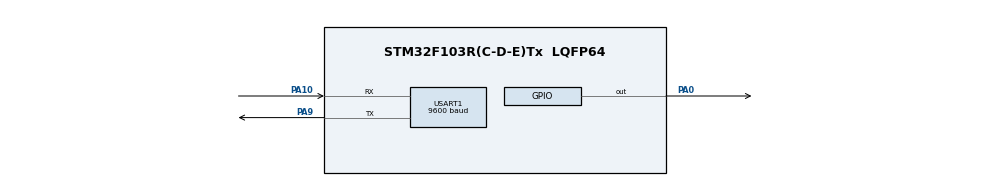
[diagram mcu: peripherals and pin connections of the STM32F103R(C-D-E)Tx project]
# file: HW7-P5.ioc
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Mcu.Family=STM32F1
Mcu.Name=STM32F103R(C-D-E)Tx
Mcu.Package=LQFP64
NVIC.PriorityGroup=NVIC_PRIORITYGROUP_4
NVIC.TIM1_CC_IRQn=true\:0\:0\:false\:false\:true\:true\:true\:true
NVIC.TIM1_UP_IRQn=true\:0\:0\:false\:false\:true\:true\:true\:true
NVIC.USART1_IRQn=true\:0\:0\:false\:false\:true\:true\:true\:true
PA0-WKUP.Signal=GPIO_Output
PA10.Mode=Asynchronous
PA10.Signal=USART1_RX
PA13.Mode=Serial_Wire
PA13.Signal=SYS_JTMS-SWDIO
PA14.Mode=Serial_Wire
PA14.Signal=SYS_JTCK-SWCLK
PA9.Mode=Asynchronous
PA9.Signal=USART1_TX
ProjectManager.HeapSize=0x200
ProjectManager.StackSize=0x400
ProjectManager.TargetToolchain=MDK-ARM V5.32
RCC.APB1Freq_Value=8000000
RCC.APB2Freq_Value=8000000
TIM1.AutoReloadPreload=TIM_AUTORELOAD_PRELOAD_ENABLE
TIM1.Channel-Output\ Compare1\ No\ Output=TIM_CHANNEL_1
TIM1.OCMode_1=TIM_OCMODE_TOGGLE
TIM1.Period=7999
TIM1.Prescaler=PonePRE
TIM1.Pulse-Output\ Compare1\ No\ Output=0
TIM1.TIM_MasterOutputTrigger=TIM_TRGO_UPDATE
USART1.BaudRate=9600
USART1.VirtualMode=VM_ASYNC
VP_TIM1_VS_ClockSourceINT.Mode=Internal
VP_TIM1_VS_no_output1.Mode=Output Compare1 No Output
board=custom

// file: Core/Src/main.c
/* USER CODE BEGIN Header */
/**
  ******************************************************************************
  * @file           : main.c
  * @brief          : Main program body
  ******************************************************************************
  * @attention
  *
  * Copyright (c) 2026 STMicroelectronics.
  * All rights reserved.
  *
  * This software is licensed under terms that can be found in the LICENSE file
  * in the root directory of this software component.
  * If no LICENSE file comes with this software, it is provided AS-IS.
  *
  ******************************************************************************
  */
/* USER CODE END Header */
#include "main.h"

/* USER CODE BEGIN Includes */
#include <stdio.h>
#include <stdlib.h>
#include <string.h>
/* USER CODE END Includes */

TIM_HandleTypeDef htim1;

UART_HandleTypeDef huart1;

/* USER CODE BEGIN PV */
uint16_t PonePRE = 79;
uint32_t target_freq = 50;   // Default 50 Hz startup
uint32_t target_duty = 2047; // Default 50% startup

uint8_t rx_buffer[2];
/* USER CODE END PV */

void SystemClock_Config(void);
static void MX_GPIO_Init(void);
static void MX_TIM1_Init(void);
static void MX_USART1_UART_Init(void);

/* USER CODE BEGIN 0 */
// UART RX Interrupt Callback to parse MATLAB commands
void HAL_UART_RxCpltCallback(UART_HandleTypeDef *huart)
{
    if (huart->Instance == USART1)
    {
        // 1. Extract the top 4 bits of the first byte to find the Command
        uint8_t command = (rx_buffer[0] >> 4) & 0x0F;

        // 2. Reconstruct the 12-bit data by combining the leftover 4 bits and the 8-bit Low Byte
        uint16_t value = ((rx_buffer[0] & 0x0F) << 8) | rx_buffer[1];

        // 3. Apply the data
        if (command == 1) // 1 = Frequency
        {
            target_freq = value;
        }
        else if (command == 2) // 2 = Duty Cycle
        {
            target_duty = value;
        }

        // Re-arm UART to wait for the next 2 bytes
        HAL_UART_Receive_IT(&huart1, rx_buffer, 2);
    }
}

// Timer Callbacks for PWM Generation
void HAL_TIM_PeriodElapsedCallback(TIM_HandleTypeDef *htim){
    if(TIM1->CCR1 > 0){
        HAL_GPIO_WritePin(GPIOA, GPIO_PIN_0, GPIO_PIN_SET);
    }
}

void HAL_TIM_OC_DelayElapsedCallback(TIM_HandleTypeDef *htim){
    if(htim->Channel == HAL_TIM_ACTIVE_CHANNEL_1){
        HAL_GPIO_WritePin(GPIOA, GPIO_PIN_0, GPIO_PIN_RESET);
    }
}
/* USER CODE END 0 */

int main(void)
{

  /* MCU Configuration--------------------------------------------------------*/

  /* Reset of all peripherals, Initializes the Flash interface and the Systick. */
  HAL_Init();

  /* Configure the system clock */
  SystemClock_Config();

  /* Initialize all configured peripherals */
  MX_GPIO_Init();
  MX_TIM1_Init();
  MX_USART1_UART_Init();
  /* USER CODE BEGIN 2 */
	// Start listening on UART immediately
	HAL_UART_Receive_IT(&huart1, rx_buffer, 2);
	/* USER CODE END 2 */

  /* Infinite loop */
  /* USER CODE BEGIN WHILE */
  while (1)
  {
		if (target_freq == 0)
      {
          HAL_TIM_Base_Stop_IT(&htim1);
          HAL_TIM_OC_Stop_IT(&htim1, TIM_CHANNEL_1);
          HAL_GPIO_WritePin(GPIOA, GPIO_PIN_0, GPIO_PIN_RESET);
      }
      else
      {
          HAL_TIM_Base_Start_IT(&htim1);
          HAL_TIM_OC_Start_IT(&htim1, TIM_CHANNEL_1);

          // 1. Calculate ARR based on target frequency
          uint32_t new_arr = (100000 / target_freq) - 1;
          if (new_arr > 65535) new_arr = 65535;

          // 2. Calculate CCR1 based on target duty (0 to 4095)
          uint32_t new_ccr = (target_duty * (new_arr + 1)) / 4095;

          // Apply hardware updates
          TIM1->ARR = new_arr;
          TIM1->CCR1 = new_ccr;
      }

      HAL_Delay(10);
    /* USER CODE END WHILE */

  }
}

void SystemClock_Config(void)
{
  RCC_OscInitTypeDef RCC_OscInitStruct = {0};
  RCC_ClkInitTypeDef RCC_ClkInitStruct = {0};

  /** Initializes the RCC Oscillators according to the specified parameters
  * in the RCC_OscInitTypeDef structure.
  */
  RCC_OscInitStruct.OscillatorType = RCC_OSCILLATORTYPE_HSI;
  RCC_OscInitStruct.HSIState = RCC_HSI_ON;
  RCC_OscInitStruct.HSICalibrationValue = RCC_HSICALIBRATION_DEFAULT;
  RCC_OscInitStruct.PLL.PLLState = RCC_PLL_NONE;
  if (HAL_RCC_OscConfig(&RCC_OscInitStruct) != HAL_OK)
  {
    Error_Handler();
  }

  /** Initializes the CPU, AHB and APB buses clocks
  */
  RCC_ClkInitStruct.ClockType = RCC_CLOCKTYPE_HCLK|RCC_CLOCKTYPE_SYSCLK
                              |RCC_CLOCKTYPE_PCLK1|RCC_CLOCKTYPE_PCLK2;
  RCC_ClkInitStruct.SYSCLKSource = RCC_SYSCLKSOURCE_HSI;
  RCC_ClkInitStruct.AHBCLKDivider = RCC_SYSCLK_DIV1;
  RCC_ClkInitStruct.APB1CLKDivider = RCC_HCLK_DIV1;
  RCC_ClkInitStruct.APB2CLKDivider = RCC_HCLK_DIV1;

  if (HAL_RCC_ClockConfig(&RCC_ClkInitStruct, FLASH_LATENCY_0) != HAL_OK)
  {
    Error_Handler();
  }
}

static void MX_TIM1_Init(void)
{

  TIM_ClockConfigTypeDef sClockSourceConfig = {0};
  TIM_MasterConfigTypeDef sMasterConfig = {0};
  TIM_OC_InitTypeDef sConfigOC = {0};
  TIM_BreakDeadTimeConfigTypeDef sBreakDeadTimeConfig = {0};

  htim1.Instance = TIM1;
  htim1.Init.Prescaler = PonePRE;
  htim1.Init.CounterMode = TIM_COUNTERMODE_UP;
  htim1.Init.Period = 7999;
  htim1.Init.ClockDivision = TIM_CLOCKDIVISION_DIV1;
  htim1.Init.RepetitionCounter = 0;
  htim1.Init.AutoReloadPreload = TIM_AUTORELOAD_PRELOAD_ENABLE;
  if (HAL_TIM_Base_Init(&htim1) != HAL_OK)
  {
    Error_Handler();
  }
  sClockSourceConfig.ClockSource = TIM_CLOCKSOURCE_INTERNAL;
  if (HAL_TIM_ConfigClockSource(&htim1, &sClockSourceConfig) != HAL_OK)
  {
    Error_Handler();
  }
  if (HAL_TIM_OC_Init(&htim1) != HAL_OK)
  {
    Error_Handler();
  }
  sMasterConfig.MasterOutputTrigger = TIM_TRGO_UPDATE;
  sMasterConfig.MasterSlaveMode = TIM_MASTERSLAVEMODE_DISABLE;
  if (HAL_TIMEx_MasterConfigSynchronization(&htim1, &sMasterConfig) != HAL_OK)
  {
    Error_Handler();
  }
  sConfigOC.OCMode = TIM_OCMODE_TOGGLE;
  sConfigOC.Pulse = 0;
  sConfigOC.OCPolarity = TIM_OCPOLARITY_HIGH;
  sConfigOC.OCNPolarity = TIM_OCNPOLARITY_HIGH;
  sConfigOC.OCFastMode = TIM_OCFAST_DISABLE;
  sConfigOC.OCIdleState = TIM_OCIDLESTATE_RESET;
  sConfigOC.OCNIdleState = TIM_OCNIDLESTATE_RESET;
  if (HAL_TIM_OC_ConfigChannel(&htim1, &sConfigOC, TIM_CHANNEL_1) != HAL_OK)
  {
    Error_Handler();
  }
  sBreakDeadTimeConfig.OffStateRunMode = TIM_OSSR_DISABLE;
  sBreakDeadTimeConfig.OffStateIDLEMode = TIM_OSSI_DISABLE;
  sBreakDeadTimeConfig.LockLevel = TIM_LOCKLEVEL_OFF;
  sBreakDeadTimeConfig.DeadTime = 0;
  sBreakDeadTimeConfig.BreakState = TIM_BREAK_DISABLE;
  sBreakDeadTimeConfig.BreakPolarity = TIM_BREAKPOLARITY_HIGH;
  sBreakDeadTimeConfig.AutomaticOutput = TIM_AUTOMATICOUTPUT_DISABLE;
  if (HAL_TIMEx_ConfigBreakDeadTime(&htim1, &sBreakDeadTimeConfig) != HAL_OK)
  {
    Error_Handler();
  }

}

static void MX_USART1_UART_Init(void)
{

  huart1.Instance = USART1;
  huart1.Init.BaudRate = 9600;
  huart1.Init.WordLength = UART_WORDLENGTH_8B;
  huart1.Init.StopBits = UART_STOPBITS_1;
  huart1.Init.Parity = UART_PARITY_NONE;
  huart1.Init.Mode = UART_MODE_TX_RX;
  huart1.Init.HwFlowCtl = UART_HWCONTROL_NONE;
  huart1.Init.OverSampling = UART_OVERSAMPLING_16;
  if (HAL_UART_Init(&huart1) != HAL_OK)
  {
    Error_Handler();
  }

}

static void MX_GPIO_Init(void)
{
  GPIO_InitTypeDef GPIO_InitStruct = {0};

  /* GPIO Ports Clock Enable */
  __HAL_RCC_GPIOA_CLK_ENABLE();

  /*Configure GPIO pin Output Level */
  HAL_GPIO_WritePin(GPIOA, GPIO_PIN_0, GPIO_PIN_RESET);

  /*Configure GPIO pin : PA0 */
  GPIO_InitStruct.Pin = GPIO_PIN_0;
  GPIO_InitStruct.Mode = GPIO_MODE_OUTPUT_PP;
  GPIO_InitStruct.Pull = GPIO_NOPULL;
  GPIO_InitStruct.Speed = GPIO_SPEED_FREQ_LOW;
  HAL_GPIO_Init(GPIOA, &GPIO_InitStruct);

}

void Error_Handler(void)
{
  __disable_irq();
  while (1)
  {
  }
}
